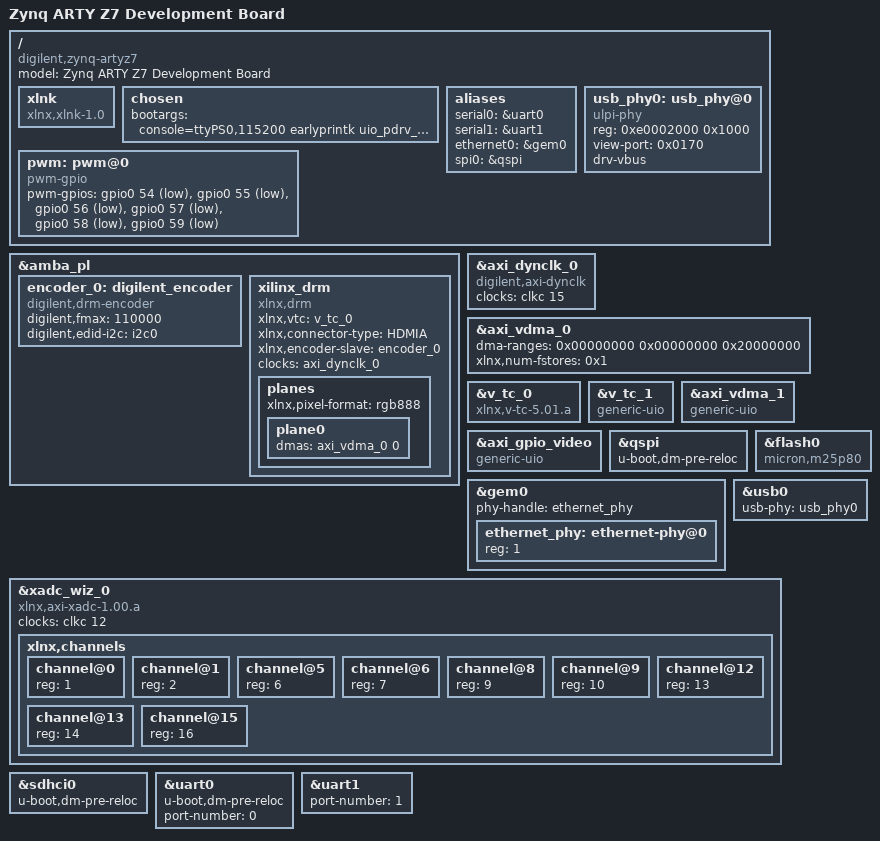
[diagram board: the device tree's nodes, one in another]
/include/ "system-conf.dtsi"
#include <dt-bindings/gpio/gpio.h>
/ {
	model = "Zynq ARTY Z7 Development Board";
	compatible = "digilent,zynq-artyz7", "xlnx,zynq-7000";

	xlnk {
		compatible = "xlnx,xlnk-1.0";
	};

	chosen {
		bootargs = "console=ttyPS0,115200 earlyprintk uio_pdrv_genirq.of_id=generic-uio quiet";
	};

	aliases {
		serial0 = &uart0;
		serial1 = &uart1;
		ethernet0 = &gem0;
		spi0 = &qspi;
	};

	usb_phy0: usb_phy@0 {
		compatible = "ulpi-phy";
		#phy-cells = <0>;
		reg = <0xe0002000 0x1000>;
		view-port = <0x0170>;
		drv-vbus;
	};

	pwm: pwm@0 {
		compatible = "pwm-gpio";
		#pwm-cells = <3>;
		pwm-gpios =
			<&gpio0 54 GPIO_ACTIVE_LOW>,
			<&gpio0 55 GPIO_ACTIVE_LOW>,
			<&gpio0 56 GPIO_ACTIVE_LOW>,
			<&gpio0 57 GPIO_ACTIVE_LOW>,
			<&gpio0 58 GPIO_ACTIVE_LOW>,
			<&gpio0 59 GPIO_ACTIVE_LOW>;
	};
};

&amba_pl {
	encoder_0: digilent_encoder {
		compatible = "digilent,drm-encoder";
		digilent,fmax = <110000>;
		digilent,edid-i2c = <&i2c0>;
	};

	xilinx_drm {
		compatible = "xlnx,drm";
		xlnx,vtc = <&v_tc_0>;
		xlnx,connector-type = "HDMIA";
		xlnx,encoder-slave = <&encoder_0>;
		clocks = <&axi_dynclk_0>;
		planes {
			xlnx,pixel-format = "rgb888";
			plane0 {
				dmas = <&axi_vdma_0 0>;
				dma-names = "dma0";
			};
		};
	};
};


&axi_dynclk_0 {
	compatible = "digilent,axi-dynclk";
	#clock-cells = <0>;
	clocks = <&clkc 15>;
};

&axi_vdma_0 {
	dma-ranges = <0x00000000 0x00000000 0x20000000>;
	xlnx,num-fstores = <0x1>;
};

&v_tc_0 {
	compatible = "xlnx,v-tc-5.01.a";
};

&v_tc_1 {
	compatible = "generic-uio";
};
&axi_vdma_1 {
	compatible = "generic-uio";	
};
&axi_gpio_video {
	compatible = "generic-uio";	
};

&qspi {
	u-boot,dm-pre-reloc;
};

&flash0 {
	compatible = "micron,m25p80", "s25fl128s";
};

&gem0 {
	phy-handle = <&ethernet_phy>;

	ethernet_phy: ethernet-phy@0 { /* rtl8211e-vl */
	reg = <1>;
	device_type = "ethernet-phy";
	};
};

&usb0 {	
	usb-phy = <&usb_phy0>;
	/delete-property/ usb-reset;
};

&xadc_wiz_0 {
	compatible = "xlnx,axi-xadc-1.00.a";
	clocks = <&clkc 12>;
	xlnx,channels {
		#address-cells = <1>;
		#size-cells = <0>;
		channel@0 { /* vaux0 */
			reg = <1>;
		};
		channel@1 {
			reg = <2>;
		};
		channel@5 {
			reg = <6>;
		};
		channel@6 {
			reg = <7>;
		};
		channel@8 {
			reg = <9>;
		};
		channel@9 {
			reg = <10>;
		};
		channel@12 {
			reg = <13>;
		};
		channel@13 {
			reg = <14>;
		};
		channel@15 {
			reg = <16>;
		};
	};
};

&sdhci0 {
	u-boot,dm-pre-reloc;
};

&uart0 {
	u-boot,dm-pre-reloc;
	port-number = <0>;	
};

&uart1 {
	port-number = <1>;
};


